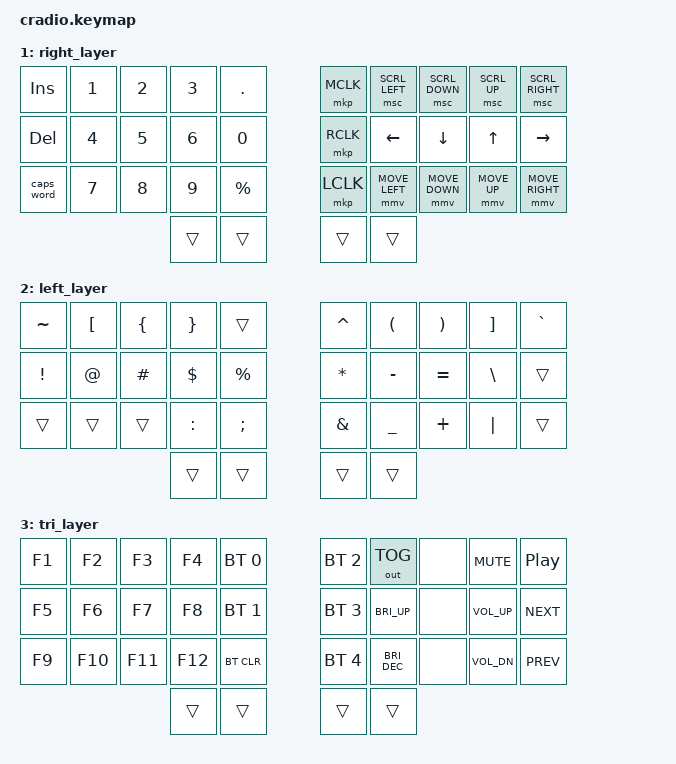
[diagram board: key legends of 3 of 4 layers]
// Copyright (c) 2024
// SPDX-License-Identifier: MIT

#include <behaviors.dtsi>
#include <dt-bindings/zmk/keys.h>
#include <dt-bindings/zmk/bt.h>
#include <dt-bindings/zmk/outputs.h>
#include <dt-bindings/zmk/pointing.h>

// Layer Definitions
#define MAC 0
#define RIG 1
#define LEF 2
#define TRI 3

// Home row mods macros
#define HRML(k1,k2,k3,k4) &hml LSHFT k1  &hml LALT k2  &hml LCTRL k3  &hml LGUI k4
#define HRMR(k1,k2,k3,k4) &hmr RGUI k1  &hmr RCTRL k2  &hmr RALT k3  &hmr RSHFT k4

// Configure pointing behaviors
&mmv {
    acceleration-exponent = <1>;
    time-to-max-speed-ms = <300>;
    delay-ms = <0>;
    x-input-code = <INPUT_REL_X>;
    y-input-code = <INPUT_REL_Y>;
};

&msc {
    acceleration-exponent = <1>;
    time-to-max-speed-ms = <300>;
    delay-ms = <0>;
    x-input-code = <INPUT_REL_HWHEEL>;
    y-input-code = <INPUT_REL_WHEEL>;
};

/ {
    behaviors {

        // Home Row Mods
        hml: hold_tap_left {
            compatible = "zmk,behavior-hold-tap";
            #binding-cells = <2>;
            flavor = "balanced";
            tapping-term-ms = <250>;
            quick-tap-ms = <200>;
            bindings = <&kp>, <&kp>;
        };

        hmr: hold_tap_right {
            compatible = "zmk,behavior-hold-tap";
            #binding-cells = <2>;
            flavor = "balanced";
            tapping-term-ms = <250>;
            quick-tap-ms = <200>;
            bindings = <&kp>, <&kp>;
        };

        // Other behaviors
        enter_hold_tap: enter_hold_tap {
            compatible = "zmk,behavior-hold-tap";
            #binding-cells = <2>;
            flavor = "tap-preferred";
            tapping-term-ms = <200>;
            bindings = <&mo>, <&kp>;
        };

        bspc_del: backspace_delete {
            compatible = "zmk,behavior-mod-morph";
            #binding-cells = <0>;
            bindings = <&kp BACKSPACE>, <&kp DELETE>;
            mods = <(MOD_LSFT|MOD_RSFT)>;
        };

        td_left: tap_dance_left {
            compatible = "zmk,behavior-tap-dance";
            #binding-cells = <0>;
            tapping-term-ms = <300>;
            bindings = <&kp ENTER>, <&tog LEF>;
        };

        td_right: tap_dance_right {
            compatible = "zmk,behavior-tap-dance";
            #binding-cells = <0>;
            tapping-term-ms = <300>;
            bindings = <&kp SPACE>, <&tog RIG>;
        };
    };

    combos {
        compatible = "zmk,combos";
        combo_esc {
            timeout-ms = <50>;
            key-positions = <0 1>;
            bindings = <&kp ESC>;
        };

        combo_backdel {
            timeout-ms = <50>;
            key-positions = <8 9>;
            bindings = <&bspc_del>;
        };

        combo_caps {
            timeout-ms = <50>;
            key-positions = <7 8>;
            bindings = <&caps_word>;
        };

        combo_mac_layer {
            timeout-ms = <50>;
            key-positions = <31 32>;
            bindings = <&to MAC>;
        };
    };

    conditional_layers {
        compatible = "zmk,conditional-layers";
        tri_layer {
            if-layers = <RIG LEF>;
            then-layer = <TRI>;
        };
    };

    keymap {
        compatible = "zmk,keymap";

        mac_layer {
            bindings = <
                &kp Q  &kp W  &kp E  &kp R  &kp T     &kp Y  &kp U  &kp I  &kp O  &kp P
                HRML(A, S, D, F)      &kp G  &kp H  HRMR(J, K, L, SQT)
                &kp Z  &kp X  &kp C  &kp V  &kp B     &kp N  &kp M  &kp COMMA  &kp DOT  &kp FSLH
                                      &lt 2 TAB  &td_left  &td_right  &lt 1 BSPC
            >;
        };
        
        right_layer {
            bindings = <
                &kp INS     &kp N1     &kp N2     &kp N3     &kp DOT        &mkp MCLK   &msc SCRL_LEFT   &msc SCRL_DOWN  &msc SCRL_UP    &msc SCRL_RIGHT  
                &kp DEL     &kp N4     &kp N5     &kp N6     &kp N0         &mkp RCLK   &kp LEFT         &kp DOWN        &kp UP          &kp RIGHT       
                &caps_word  &kp N7     &kp N8     &kp N9     &kp PRCNT      &mkp LCLK   &mmv MOVE_LEFT   &mmv MOVE_DOWN  &mmv MOVE_UP    &mmv MOVE_RIGHT  
                                                  &trans     &trans         &trans      &trans
            >;
        };

        left_layer {
            bindings = <
                &kp TILDE  &kp LBKT   &kp LBRC   &kp RBRC   &trans          &kp CARET  &kp LPAR   &kp RPAR   &kp RBKT   &kp GRAVE
                &kp EXCL   &kp AT     &kp HASH   &kp DLLR   &kp PRCNT       &kp ASTRK  &kp MINUS  &kp EQUAL  &kp BSLH   &trans
                &trans     &trans     &trans     &kp COLON  &kp SEMI        &kp AMPS   &kp UNDER  &kp PLUS   &kp PIPE   &trans
                                                 &trans     &trans          &trans     &trans
            >;
        }; 
        
        tri_layer {
            bindings = <
                &kp F1     &kp F2     &kp F3     &kp F4     &bt BT_SEL 0     &bt BT_SEL 2  &out OUT_TOG  &none   &kp C_MUTE    &kp C_PP
                &kp F5     &kp F6     &kp F7     &kp F8     &bt BT_SEL 1     &bt BT_SEL 3  &kp C_BRI_UP  &none   &kp C_VOL_UP  &kp C_NEXT
                &kp F9     &kp F10    &kp F11    &kp F12    &bt BT_CLR       &bt BT_SEL 4  &kp C_BRI_DEC &none   &kp C_VOL_DN  &kp C_PREV
                                                 &trans     &trans           &trans        &trans
            >;
        };
    };
};
